AUTOSAR XML (schema 00052)
package /katech/AdaptiveApplicationSwComponentTypes
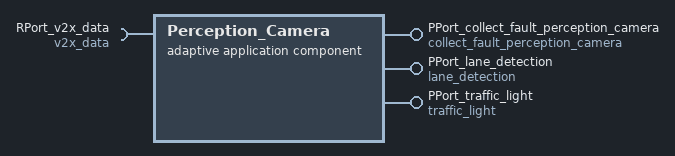
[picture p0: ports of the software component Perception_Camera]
  adaptive application sw component type Perception_Camera
    provide port PPort_collect_fault_perception_camera: provided-interface=collect_fault_perception_camera
    provide port PPort_lane_detection: provided-interface=lane_detection
    provide port PPort_traffic_light: provided-interface=traffic_light
    require port RPort_v2x_data: required-interface=v2x_data
package /katech/Executables
  executable Perception_Camera: category=APPLICATION_LEVEL, minimum-timer-granularity=1000
    root sw component prototype Perception_Camera: application-type=Perception_Camera
